# MKM34Z7 register map
Vendor: Freescale Semiconductor, Inc.; Series: Kinetis_M; File version: 1.6
CPU: CM0PLUS r0p0, little endian, no MPU, no FPU, VTOR, 2 interrupt priority bits
Registers are 8-bit, read-write, reset 0x0 unless marked. A register's access mark holds for its fields unless they carry their own. Offsets are from the block's base; [hi:lo] are bit positions; {n}, {i} and the like mark numbered series; 'fields as' and 'values as' point back to an identical list.

## CRC — Cyclic Redundancy Check
Base 0x40034000; register names take the prefix CRC_
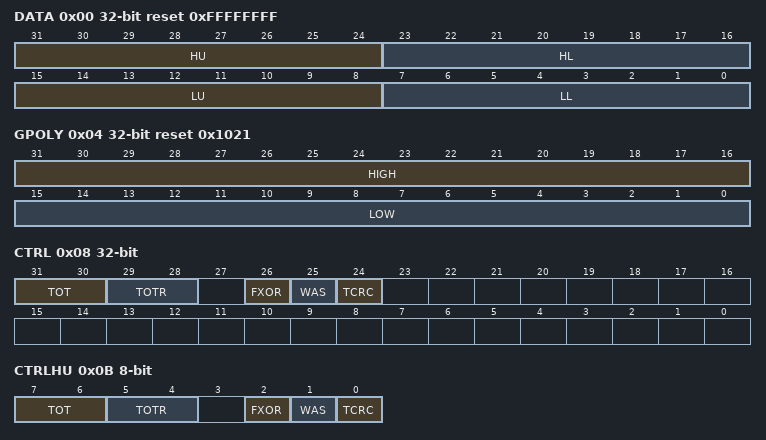
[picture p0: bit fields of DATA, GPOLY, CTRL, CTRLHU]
0x00 DATA 32-bit reset 0xFFFFFFFF (CRC view) — CRC Data register
  [31:24] HU — CRC High Upper Byte
  [23:16] HL — CRC High Lower Byte
  [15:8] LU — CRC Low Upper Byte
  [7:0] LL — CRC Low Lower Byte
0x00 DATAL 16-bit reset 0xFFFF (CRC view) — CRC_DATAL register.
  [15:0] DATAL — DATAL stores the lower 16 bits of the 16/32 bit CRC
0x00 DATALL reset 0xFF (CRC view) — CRC_DATALL register.
  [7:0] DATALL — CRCLL stores the first 8 bits of the 32 bit DATA
0x01 DATALU reset 0xFF — CRC_DATALU register.
  [7:0] DATALU — DATALL stores the second 8 bits of the 32 bit CRC
0x02 DATAH 16-bit reset 0xFFFF (CRC view) — CRC_DATAH register.
  [15:0] DATAH — DATAH stores the high 16 bits of the 16/32 bit CRC
0x02 DATAHL reset 0xFF (CRC view) — CRC_DATAHL register.
  [7:0] DATAHL — DATAHL stores the third 8 bits of the 32 bit CRC
0x03 DATAHU reset 0xFF — CRC_DATAHU register.
  [7:0] DATAHU — DATAHU stores the fourth 8 bits of the 32 bit CRC
0x04 GPOLY 32-bit reset 0x1021 (CRC view) — CRC Polynomial register
  [31:16] HIGH — High Polynominal Half-word
  [15:0] LOW — Low Polynominal Half-word
0x04 GPOLYL 16-bit reset 0xFFFF (CRC view) — CRC_GPOLYL register.
  [15:0] GPOLYL — POLYL stores the lower 16 bits of the 16/32 bit CRC polynomial value
0x04 GPOLYLL reset 0xFF (CRC view) — CRC_GPOLYLL register.
  [7:0] GPOLYLL — POLYLL stores the first 8 bits of the 32 bit CRC
0x05 GPOLYLU reset 0xFF — CRC_GPOLYLU register.
  [7:0] GPOLYLU — POLYLL stores the second 8 bits of the 32 bit CRC
0x06 GPOLYH 16-bit reset 0xFFFF (CRC view) — CRC_GPOLYH register.
  [15:0] GPOLYH — POLYH stores the high 16 bits of the 16/32 bit CRC polynomial value
0x06 GPOLYHL reset 0xFF (CRC view) — CRC_GPOLYHL register.
  [7:0] GPOLYHL — POLYHL stores the third 8 bits of the 32 bit CRC
0x07 GPOLYHU reset 0xFF — CRC_GPOLYHU register.
  [7:0] GPOLYHU — POLYHU stores the fourth 8 bits of the 32 bit CRC
0x08 CTRL 32-bit — CRC Control register
  [31:30] TOT — Type Of Transpose For Writes
    0=No transposition; 1=Bits in bytes are transposed; bytes are not transposed; 2=Both bits in bytes and bytes are transposed; 3=Only bytes are transposed; no bits in a byte are transposed
  [29:28] TOTR — Type Of Transpose For Read
    values as TOT
  [26] FXOR — Complement Read Of CRC Data Register
    0=No XOR on reading; 1=Invert or complement the read value of the CRC Data register
  [25] WAS — Write CRC Data Register As Seed
    0=Writes to the CRC data register are data values; 1=Writes to the CRC data register are seed values
  [24] TCRC
    0=16-bit CRC protocol; 1=32-bit CRC protocol
0x0B CTRLHU — CRC_CTRLHU register.
  [7:6] TOT
    0=No Transposition; 1=Bits in bytes are transposed, bytes are not transposed; 2=Both bits in bytes and bytes are transposed; 3=Only bytes are transposed; no bits in a byte are transposed
  [5:4] TOTR
    values as TOT
  [2] FXOR
    0=No XOR on reading; 1=Invert or complement the read value of CRC data register
  [1] WAS
    0=Writes to CRC data register are data values; 1=Writes to CRC data reguster are seed values
  [0] TCRC
    0=16-bit CRC protocol; 1=32-bit CRC protocol

## PORTM — Pin Control and Interrupts
Base 0x4003A000; register names take the prefix PORTM_
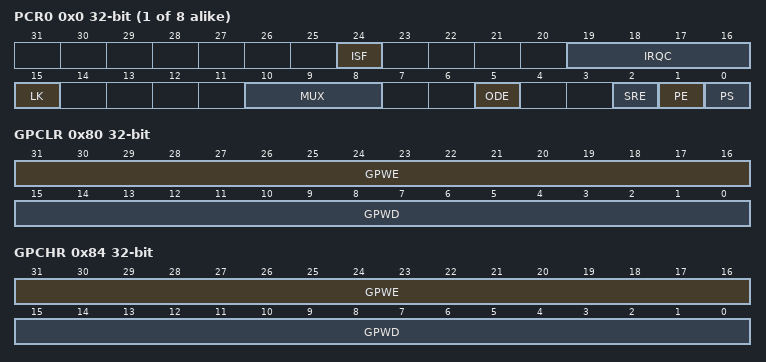
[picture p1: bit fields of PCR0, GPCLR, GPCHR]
{0x0+4i} PCR{i} (i=0..7) 32-bit — Pin Control Register n
  [24] ISF — Interrupt Status Flag
    0=Configured interrupt is not detected; 1=Configured interrupt is detected. If the pin is configured to generate a DMA request, then the corresponding flag will be cleared automatically at the completion of the requested DMA transfer. Otherwise, the flag remains set until a logic 1 is written to the flag. If the pin is configured for a level sensitive interrupt and the pin remains asserted, then the flag is set again immediately after it is cleared.
  [19:16] IRQC — Interrupt Configuration
    0=Interrupt Status Flag (ISF) is disabled; 1=ISF flag and DMA request on rising edge; 2=ISF flag and DMA request on falling edge; 3=ISF flag and DMA request on either edge; 8=ISF flag and Interrupt when logic 0; 9=ISF flag and Interrupt on rising-edge; 10=ISF flag and Interrupt on falling-edge; 11=ISF flag and Interrupt on either edge; 12=ISF flag and Interrupt when logic 1
  [15] LK — Lock Register
    0=Pin Control Register fields [15:0] are not locked; 1=Pin Control Register fields [15:0] are locked and cannot be updated until the next system reset
  [10:8] MUX — Pin Mux Control
    0=Pin disabled (analog); 1=Alternative 1 (GPIO); {v}=Alternative {v} (chip-specific) (v=2..7)
  [5] ODE — Open Drain Enable
    0=Open drain output is disabled on the corresponding pin; 1=Open drain output is enabled on the corresponding pin, if the pin is configured as a digital output
  [2] SRE — Slew Rate Enable
    0=Fast slew rate is configured on the corresponding pin, if the pin is configured as a digital output; 1=Slow slew rate is configured on the corresponding pin, if the pin is configured as a digital output
  [1] PE — Pull Enable
    0=Internal pullup or pulldown resistor is not enabled on the corresponding pin; 1=Internal pullup or pulldown resistor is enabled on the corresponding pin, if the pin is configured as a digital input
  [0] PS — Pull Select
    0=Internal pulldown resistor is enabled on the corresponding pin, if the corresponding PE field is set; 1=Internal pullup resistor is enabled on the corresponding pin, if the corresponding PE field is set
0x80 GPCLR 32-bit wo — Global Pin Control Low Register
  [31:16] GPWE — Global Pin Write Enable
    0=Corresponding Pin Control Register is not updated with the value in GPWD; 1=Corresponding Pin Control Register is updated with the value in GPWD
  [15:0] GPWD — Global Pin Write Data
0x84 GPCHR 32-bit wo — Global Pin Control High Register
  fields as GPCLR
0xA0 ISFR 32-bit — Interrupt Status Flag Register
  [31:0] ISF — Interrupt Status Flag
    values as PCR0.ISF

## Notices in the file
Redistribution and use in source and binary forms, with or without modification,
are permitted provided that the following conditions are met:
o Redistributions of source code must retain the above copyright notice, this list
of conditions and the following disclaimer.
o Redistributions in binary form must reproduce the above copyright notice, this
list of conditions and the following disclaimer in the documentation and/or
other materials provided with the distribution.
o Neither the name of Freescale Semiconductor, Inc. nor the names of its
contributors may be used to endorse or promote products derived from this
software without specific prior written permission.
THIS SOFTWARE IS PROVIDED BY THE COPYRIGHT HOLDERS AND CONTRIBUTORS "AS IS" AND
ANY EXPRESS OR IMPLIED WARRANTIES, INCLUDING, BUT NOT LIMITED TO, THE IMPLIED
WARRANTIES OF MERCHANTABILITY AND FITNESS FOR A PARTICULAR PURPOSE ARE
DISCLAIMED. IN NO EVENT SHALL THE COPYRIGHT HOLDER OR CONTRIBUTORS BE LIABLE FOR
ANY DIRECT, INDIRECT, INCIDENTAL, SPECIAL, EXEMPLARY, OR CONSEQUENTIAL DAMAGES
(INCLUDING, BUT NOT LIMITED TO, PROCUREMENT OF SUBSTITUTE GOODS OR SERVICES;
LOSS OF USE, DATA, OR PROFITS; OR BUSINESS INTERRUPTION) HOWEVER CAUSED AND ON
ANY THEORY OF LIABILITY, WHETHER IN CONTRACT, STRICT LIABILITY, OR TORT
(INCLUDING NEGLIGENCE OR OTHERWISE) ARISING IN ANY WAY OUT OF THE USE OF THIS
SOFTWARE, EVEN IF ADVISED OF THE POSSIBILITY OF SUCH DAMAGE.
